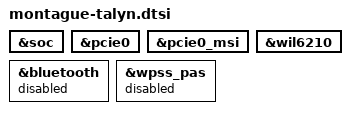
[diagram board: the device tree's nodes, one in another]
// SPDX-License-Identifier: BSD-3-Clause
/*
 * Copyright (c) Qualcomm Technologies, Inc. and/or its subsidiaries.
 */

#include "ravelin-idp.dtsi"
#include "ravelin-qcx6438.dtsi"

&soc {
};

&pcie0 {
	status = "ok";
};

&pcie0_msi {
	status = "ok";
};

&wil6210 {
	status = "ok";
};

&bluetooth {
	status = "disabled";
};

&wpss_pas {
	status = "disabled";
};
